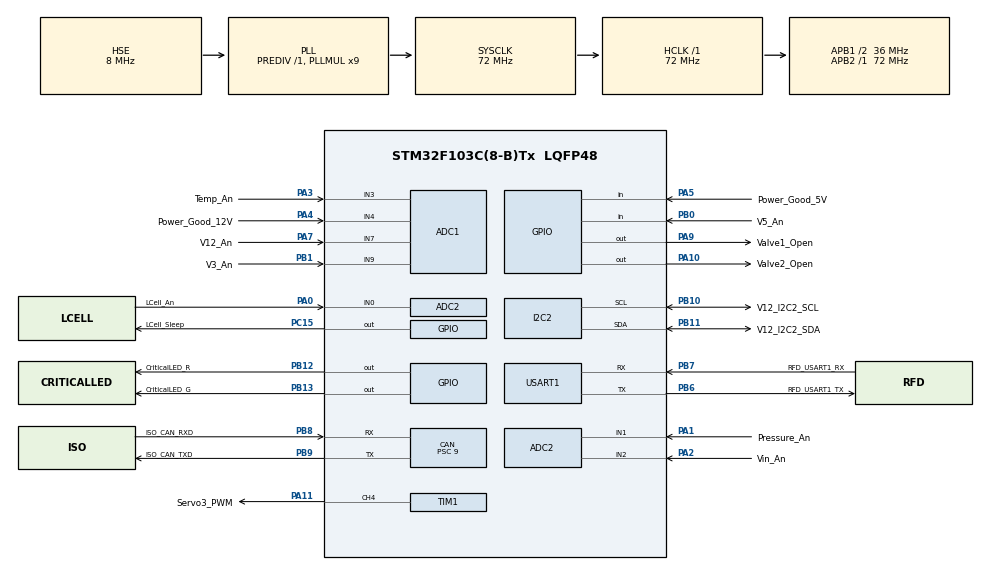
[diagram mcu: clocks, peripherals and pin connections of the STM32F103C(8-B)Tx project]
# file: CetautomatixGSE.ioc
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ADC1.Channel-0\#ChannelRegularConversion=ADC_CHANNEL_3
ADC1.Channel-1\#ChannelRegularConversion=ADC_CHANNEL_4
ADC1.Channel-2\#ChannelRegularConversion=ADC_CHANNEL_7
ADC1.Channel-3\#ChannelRegularConversion=ADC_CHANNEL_9
ADC1.ExternalTrigConv=ADC_EXTERNALTRIGCONV_T3_TRGO
ADC1.Mode=ADC_DUALMODE_REGSIMULT
ADC1.NbrOfConversion=4
ADC1.NbrOfConversionFlag=1
ADC1.Rank-0\#ChannelRegularConversion=1
ADC1.Rank-1\#ChannelRegularConversion=2
ADC1.Rank-2\#ChannelRegularConversion=3
ADC1.Rank-3\#ChannelRegularConversion=4
ADC1.SamplingTime-0\#ChannelRegularConversion=ADC_SAMPLETIME_71CYCLES_5
ADC1.SamplingTime-1\#ChannelRegularConversion=ADC_SAMPLETIME_71CYCLES_5
ADC1.SamplingTime-2\#ChannelRegularConversion=ADC_SAMPLETIME_71CYCLES_5
ADC1.SamplingTime-3\#ChannelRegularConversion=ADC_SAMPLETIME_71CYCLES_5
ADC1.master=1
ADC2.Channel-0\#ChannelRegularConversion=ADC_CHANNEL_0
ADC2.Channel-1\#ChannelRegularConversion=ADC_CHANNEL_1
ADC2.Channel-2\#ChannelRegularConversion=ADC_CHANNEL_2
ADC2.Channel-3\#ChannelRegularConversion=ADC_CHANNEL_2
ADC2.Mode=ADC_DUALMODE_REGSIMULT
ADC2.NbrOfConversion=4
ADC2.NbrOfConversionFlag=1
ADC2.Rank-0\#ChannelRegularConversion=1
ADC2.Rank-1\#ChannelRegularConversion=2
ADC2.Rank-2\#ChannelRegularConversion=3
ADC2.Rank-3\#ChannelRegularConversion=4
ADC2.SamplingTime-0\#ChannelRegularConversion=ADC_SAMPLETIME_71CYCLES_5
ADC2.SamplingTime-1\#ChannelRegularConversion=ADC_SAMPLETIME_71CYCLES_5
ADC2.SamplingTime-2\#ChannelRegularConversion=ADC_SAMPLETIME_71CYCLES_5
ADC2.SamplingTime-3\#ChannelRegularConversion=ADC_SAMPLETIME_71CYCLES_5
CAN.ABOM=ENABLE
CAN.BS1=CAN_BS1_13TQ
CAN.BS2=CAN_BS2_2TQ
CAN.CalculateBaudRate=250000
CAN.CalculateTimeBit=4000
CAN.CalculateTimeQuantum=250.0
CAN.NART=ENABLE
CAN.Prescaler=9
Dma.ADC1.0.Direction=DMA_PERIPH_TO_MEMORY
Dma.ADC1.0.Instance=DMA1_Channel1
Dma.ADC1.0.MemDataAlignment=DMA_MDATAALIGN_WORD
Dma.ADC1.0.MemInc=DMA_MINC_ENABLE
Dma.ADC1.0.Mode=DMA_CIRCULAR
Dma.ADC1.0.PeriphDataAlignment=DMA_PDATAALIGN_WORD
Dma.ADC1.0.PeriphInc=DMA_PINC_DISABLE
Dma.ADC1.0.Priority=DMA_PRIORITY_MEDIUM
Dma.Request0=ADC1
Dma.Request1=USART1_RX
Dma.Request2=USART1_TX
Dma.USART1_RX.1.Direction=DMA_PERIPH_TO_MEMORY
Dma.USART1_RX.1.Instance=DMA1_Channel5
Dma.USART1_RX.1.MemDataAlignment=DMA_MDATAALIGN_BYTE
Dma.USART1_RX.1.MemInc=DMA_MINC_ENABLE
Dma.USART1_RX.1.Mode=DMA_NORMAL
Dma.USART1_RX.1.PeriphDataAlignment=DMA_PDATAALIGN_BYTE
Dma.USART1_RX.1.PeriphInc=DMA_PINC_DISABLE
Dma.USART1_RX.1.Priority=DMA_PRIORITY_HIGH
Dma.USART1_TX.2.Direction=DMA_MEMORY_TO_PERIPH
Dma.USART1_TX.2.Instance=DMA1_Channel4
Dma.USART1_TX.2.MemDataAlignment=DMA_MDATAALIGN_BYTE
Dma.USART1_TX.2.MemInc=DMA_MINC_ENABLE
Dma.USART1_TX.2.Mode=DMA_NORMAL
Dma.USART1_TX.2.PeriphDataAlignment=DMA_PDATAALIGN_BYTE
Dma.USART1_TX.2.PeriphInc=DMA_PINC_DISABLE
Dma.USART1_TX.2.Priority=DMA_PRIORITY_LOW
I2C2.I2C_Mode=I2C_Fast
Mcu.Family=STM32F1
Mcu.Name=STM32F103C(8-B)Tx
Mcu.Package=LQFP48
NVIC.CAN1_RX1_IRQn=true\:0\:0\:false\:false\:true\:true\:true\:true
NVIC.CAN1_SCE_IRQn=true\:0\:0\:false\:false\:true\:true\:true\:true
NVIC.DMA1_Channel1_IRQn=true\:0\:0\:false\:false\:true\:false\:true\:true
NVIC.DMA1_Channel4_IRQn=true\:0\:0\:false\:false\:true\:false\:true\:true
NVIC.DMA1_Channel5_IRQn=true\:0\:0\:false\:false\:true\:false\:true\:true
NVIC.PriorityGroup=NVIC_PRIORITYGROUP_4
NVIC.USART1_IRQn=true\:0\:0\:false\:false\:true\:true\:true\:true
NVIC.USB_LP_CAN1_RX0_IRQn=true\:0\:0\:false\:false\:true\:true\:true\:true
PA0-WKUP.GPIO_Label=LCell_An
PA0-WKUP.Signal=ADCx_IN0
PA1.GPIO_Label=Pressure_An
PA1.Signal=ADCx_IN1
PA10.GPIO_Label=Valve2_Open
PA10.Signal=GPIO_Output
PA11.GPIO_Label=Servo3_PWM
PA11.Signal=S_TIM1_CH4
PA13.GPIO_Label=SYS_SWDIO
PA13.Mode=Trace_Asynchronous_SW
PA13.Signal=SYS_JTMS-SWDIO
PA14.GPIO_Label=SYS_SWCLK
PA14.Mode=Trace_Asynchronous_SW
PA14.Signal=SYS_JTCK-SWCLK
PA2.GPIO_Label=Vin_An
PA2.Signal=ADCx_IN2
PA3.GPIO_Label=Temp_An
PA3.Signal=ADCx_IN3
PA4.GPIO_Label=Power_Good_12V
PA4.Signal=ADCx_IN4
PA5.GPIO_Label=Power_Good_5V
PA5.Signal=GPIO_Input
PA7.GPIO_Label=V12_An
PA7.Signal=ADCx_IN7
PA9.GPIO_Label=Valve1_Open
PA9.Signal=GPIO_Output
PB0.GPIO_Label=V5_An
PB0.Signal=GPIO_Input
PB1.GPIO_Label=V3_An
PB1.Signal=ADCx_IN9
PB10.GPIO_Label=V12_I2C2_SCL
PB10.Mode=I2C
PB10.Signal=I2C2_SCL
PB11.GPIO_Label=V12_I2C2_SDA
PB11.Mode=I2C
PB11.Signal=I2C2_SDA
PB12.GPIO_Label=CriticalLED_R
PB12.Signal=GPIO_Output
PB13.GPIO_Label=CriticalLED_G
PB13.Signal=GPIO_Output
PB3.GPIO_Label=SYS_SWO
PB3.Mode=Trace_Asynchronous_SW
PB3.Signal=SYS_JTDO-TRACESWO
PB6.GPIO_Label=RFD_USART1_TX
PB6.Mode=Asynchronous
PB6.Signal=USART1_TX
PB7.GPIO_Label=RFD_USART1_RX
PB7.Mode=Asynchronous
PB7.Signal=USART1_RX
PB8.GPIO_Label=ISO_CAN_RXD
PB8.Mode=CAN_Activate
PB8.Signal=CAN_RX
PB9.GPIO_Label=ISO_CAN_TXD
PB9.Mode=CAN_Activate
PB9.Signal=CAN_TX
PC15-OSC32_OUT.GPIO_Label=LCell_Sleep
PC15-OSC32_OUT.Signal=GPIO_Output
PD0-OSC_IN.GPIO_Label=OSC_IN
PD0-OSC_IN.Mode=HSE-External-Oscillator
PD0-OSC_IN.Signal=RCC_OSC_IN
PD1-OSC_OUT.GPIO_Label=OSC_OUT
PD1-OSC_OUT.Mode=HSE-External-Oscillator
PD1-OSC_OUT.Signal=RCC_OSC_OUT
ProjectManager.HeapSize=0x200
ProjectManager.StackSize=0x400
ProjectManager.TargetToolchain=STM32CubeIDE
RCC.ADCPresc=RCC_ADCPCLK2_DIV6
RCC.AHBFreq_Value=72000000
RCC.APB1CLKDivider=RCC_HCLK_DIV2
RCC.APB1Freq_Value=36000000
RCC.APB1TimFreq_Value=72000000
RCC.APB2Freq_Value=72000000
RCC.APB2TimFreq_Value=72000000
RCC.HCLKFreq_Value=72000000
RCC.PLLMUL=RCC_PLL_MUL9
RCC.PLLSourceVirtual=RCC_PLLSOURCE_HSE
RCC.SYSCLKFreq_VALUE=72000000
RCC.SYSCLKSource=RCC_SYSCLKSOURCE_PLLCLK
RCC.USBFreq_Value=72000000
SH.ADCx_IN0.0=ADC2_IN0,IN0
SH.ADCx_IN1.0=ADC2_IN1,IN1
SH.ADCx_IN2.0=ADC2_IN2,IN2
SH.ADCx_IN3.0=ADC1_IN3,IN3
SH.ADCx_IN4.0=ADC1_IN4,IN4
SH.ADCx_IN7.0=ADC1_IN7,IN7
SH.ADCx_IN9.0=ADC1_IN9,IN9
SH.S_TIM1_CH4.0=TIM1_CH4,PWM Generation4 CH4
TIM1.Channel-PWM\ Generation4\ CH4=TIM_CHANNEL_4
TIM3.Period=999
TIM3.Prescaler=287
TIM3.TIM_MasterOutputTrigger=TIM_TRGO_UPDATE
USART1.VirtualMode=VM_ASYNC
VP_CRC_VS_CRC.Mode=CRC_Activate
VP_TIM1_VS_ClockSourceINT.Mode=Internal
VP_TIM3_VS_ClockSourceINT.Mode=Internal
board=custom

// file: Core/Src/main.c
/* USER CODE BEGIN Header */
/**
  ******************************************************************************
  * @file           : main.c
  * @brief          : Main program body
  ******************************************************************************
  * @attention
  *
  * Copyright (c) 2026 STMicroelectronics.
  * All rights reserved.
  *
  * This software is licensed under terms that can be found in the LICENSE file
  * in the root directory of this software component.
  * If no LICENSE file comes with this software, it is provided AS-IS.
  *
  ******************************************************************************
  */
/* USER CODE END Header */
#include <GAUL/Drivers/can_fifo.h>
#include <GAUL/Drivers/rfd900x.h>
#include "main.h"

ADC_HandleTypeDef hadc1;
ADC_HandleTypeDef hadc2;
DMA_HandleTypeDef hdma_adc1;

CAN_HandleTypeDef hcan;

CRC_HandleTypeDef hcrc;

I2C_HandleTypeDef hi2c2;

TIM_HandleTypeDef htim1;
TIM_HandleTypeDef htim3;

UART_HandleTypeDef huart1;
DMA_HandleTypeDef hdma_usart1_rx;
DMA_HandleTypeDef hdma_usart1_tx;

/* USER CODE BEGIN PV */
rfd900x_t rfd_dev;
can_t can_dev;
/* USER CODE END PV */

void SystemClock_Config(void);
static void MX_GPIO_Init(void);
static void MX_DMA_Init(void);
static void MX_ADC2_Init(void);
static void MX_CAN_Init(void);
static void MX_CRC_Init(void);
static void MX_TIM1_Init(void);
static void MX_ADC1_Init(void);
static void MX_USART1_UART_Init(void);
static void MX_I2C2_Init(void);
static void MX_TIM3_Init(void);

int main(void)
{

  /* MCU Configuration--------------------------------------------------------*/

  /* Reset of all peripherals, Initializes the Flash interface and the Systick. */
  HAL_Init();

  /* Configure the system clock */
  SystemClock_Config();

  /* Initialize all configured peripherals */
  MX_GPIO_Init();
  MX_DMA_Init();
  MX_ADC2_Init();
  MX_CAN_Init();
  MX_CRC_Init();
  MX_TIM1_Init();
  MX_ADC1_Init();
  MX_USART1_UART_Init();
  MX_I2C2_Init();
  MX_TIM3_Init();

  /* Infinite loop */
  while (1)
  {

  }
}

void SystemClock_Config(void)
{
  RCC_OscInitTypeDef RCC_OscInitStruct = {0};
  RCC_ClkInitTypeDef RCC_ClkInitStruct = {0};
  RCC_PeriphCLKInitTypeDef PeriphClkInit = {0};

  /** Initializes the RCC Oscillators according to the specified parameters
  * in the RCC_OscInitTypeDef structure.
  */
  RCC_OscInitStruct.OscillatorType = RCC_OSCILLATORTYPE_HSE;
  RCC_OscInitStruct.HSEState = RCC_HSE_ON;
  RCC_OscInitStruct.HSEPredivValue = RCC_HSE_PREDIV_DIV1;
  RCC_OscInitStruct.HSIState = RCC_HSI_ON;
  RCC_OscInitStruct.PLL.PLLState = RCC_PLL_ON;
  RCC_OscInitStruct.PLL.PLLSource = RCC_PLLSOURCE_HSE;
  RCC_OscInitStruct.PLL.PLLMUL = RCC_PLL_MUL9;
  if (HAL_RCC_OscConfig(&RCC_OscInitStruct) != HAL_OK)
  {
    Error_Handler();
  }

  /** Initializes the CPU, AHB and APB buses clocks
  */
  RCC_ClkInitStruct.ClockType = RCC_CLOCKTYPE_HCLK|RCC_CLOCKTYPE_SYSCLK
                              |RCC_CLOCKTYPE_PCLK1|RCC_CLOCKTYPE_PCLK2;
  RCC_ClkInitStruct.SYSCLKSource = RCC_SYSCLKSOURCE_PLLCLK;
  RCC_ClkInitStruct.AHBCLKDivider = RCC_SYSCLK_DIV1;
  RCC_ClkInitStruct.APB1CLKDivider = RCC_HCLK_DIV2;
  RCC_ClkInitStruct.APB2CLKDivider = RCC_HCLK_DIV1;

  if (HAL_RCC_ClockConfig(&RCC_ClkInitStruct, FLASH_LATENCY_2) != HAL_OK)
  {
    Error_Handler();
  }
  PeriphClkInit.PeriphClockSelection = RCC_PERIPHCLK_ADC;
  PeriphClkInit.AdcClockSelection = RCC_ADCPCLK2_DIV6;
  if (HAL_RCCEx_PeriphCLKConfig(&PeriphClkInit) != HAL_OK)
  {
    Error_Handler();
  }
}

static void MX_ADC1_Init(void)
{

  ADC_MultiModeTypeDef multimode = {0};
  ADC_ChannelConfTypeDef sConfig = {0};

  /** Common config
  */
  hadc1.Instance = ADC1;
  hadc1.Init.ScanConvMode = ADC_SCAN_ENABLE;
  hadc1.Init.ContinuousConvMode = DISABLE;
  hadc1.Init.DiscontinuousConvMode = DISABLE;
  hadc1.Init.ExternalTrigConv = ADC_EXTERNALTRIGCONV_T3_TRGO;
  hadc1.Init.DataAlign = ADC_DATAALIGN_RIGHT;
  hadc1.Init.NbrOfConversion = 4;
  if (HAL_ADC_Init(&hadc1) != HAL_OK)
  {
    Error_Handler();
  }

  /** Configure the ADC multi-mode
  */
  multimode.Mode = ADC_DUALMODE_REGSIMULT;
  if (HAL_ADCEx_MultiModeConfigChannel(&hadc1, &multimode) != HAL_OK)
  {
    Error_Handler();
  }

  /** Configure Regular Channel
  */
  sConfig.Channel = ADC_CHANNEL_3;
  sConfig.Rank = ADC_REGULAR_RANK_1;
  sConfig.SamplingTime = ADC_SAMPLETIME_71CYCLES_5;
  if (HAL_ADC_ConfigChannel(&hadc1, &sConfig) != HAL_OK)
  {
    Error_Handler();
  }

  /** Configure Regular Channel
  */
  sConfig.Channel = ADC_CHANNEL_4;
  sConfig.Rank = ADC_REGULAR_RANK_2;
  if (HAL_ADC_ConfigChannel(&hadc1, &sConfig) != HAL_OK)
  {
    Error_Handler();
  }

  /** Configure Regular Channel
  */
  sConfig.Channel = ADC_CHANNEL_7;
  sConfig.Rank = ADC_REGULAR_RANK_3;
  if (HAL_ADC_ConfigChannel(&hadc1, &sConfig) != HAL_OK)
  {
    Error_Handler();
  }

  /** Configure Regular Channel
  */
  sConfig.Channel = ADC_CHANNEL_9;
  sConfig.Rank = ADC_REGULAR_RANK_4;
  if (HAL_ADC_ConfigChannel(&hadc1, &sConfig) != HAL_OK)
  {
    Error_Handler();
  }

}

static void MX_ADC2_Init(void)
{

  ADC_ChannelConfTypeDef sConfig = {0};

  /** Common config
  */
  hadc2.Instance = ADC2;
  hadc2.Init.ScanConvMode = ADC_SCAN_ENABLE;
  hadc2.Init.ContinuousConvMode = DISABLE;
  hadc2.Init.DiscontinuousConvMode = DISABLE;
  hadc2.Init.ExternalTrigConv = ADC_SOFTWARE_START;
  hadc2.Init.DataAlign = ADC_DATAALIGN_RIGHT;
  hadc2.Init.NbrOfConversion = 4;
  if (HAL_ADC_Init(&hadc2) != HAL_OK)
  {
    Error_Handler();
  }

  /** Configure Regular Channel
  */
  sConfig.Channel = ADC_CHANNEL_0;
  sConfig.Rank = ADC_REGULAR_RANK_1;
  sConfig.SamplingTime = ADC_SAMPLETIME_71CYCLES_5;
  if (HAL_ADC_ConfigChannel(&hadc2, &sConfig) != HAL_OK)
  {
    Error_Handler();
  }

  /** Configure Regular Channel
  */
  sConfig.Channel = ADC_CHANNEL_1;
  sConfig.Rank = ADC_REGULAR_RANK_2;
  if (HAL_ADC_ConfigChannel(&hadc2, &sConfig) != HAL_OK)
  {
    Error_Handler();
  }

  /** Configure Regular Channel
  */
  sConfig.Channel = ADC_CHANNEL_2;
  sConfig.Rank = ADC_REGULAR_RANK_3;
  if (HAL_ADC_ConfigChannel(&hadc2, &sConfig) != HAL_OK)
  {
    Error_Handler();
  }

  /** Configure Regular Channel
  */
  sConfig.Rank = ADC_REGULAR_RANK_4;
  if (HAL_ADC_ConfigChannel(&hadc2, &sConfig) != HAL_OK)
  {
    Error_Handler();
  }

}

static void MX_CAN_Init(void)
{

  hcan.Instance = CAN1;
  hcan.Init.Prescaler = 9;
  hcan.Init.Mode = CAN_MODE_NORMAL;
  hcan.Init.SyncJumpWidth = CAN_SJW_1TQ;
  hcan.Init.TimeSeg1 = CAN_BS1_13TQ;
  hcan.Init.TimeSeg2 = CAN_BS2_2TQ;
  hcan.Init.TimeTriggeredMode = DISABLE;
  hcan.Init.AutoBusOff = ENABLE;
  hcan.Init.AutoWakeUp = DISABLE;
  hcan.Init.AutoRetransmission = ENABLE;
  hcan.Init.ReceiveFifoLocked = DISABLE;
  hcan.Init.TransmitFifoPriority = DISABLE;
  if (HAL_CAN_Init(&hcan) != HAL_OK)
  {
    Error_Handler();
  }

}

static void MX_CRC_Init(void)
{

  hcrc.Instance = CRC;
  if (HAL_CRC_Init(&hcrc) != HAL_OK)
  {
    Error_Handler();
  }

}

static void MX_I2C2_Init(void)
{

  hi2c2.Instance = I2C2;
  hi2c2.Init.ClockSpeed = 400000;
  hi2c2.Init.DutyCycle = I2C_DUTYCYCLE_2;
  hi2c2.Init.OwnAddress1 = 0;
  hi2c2.Init.AddressingMode = I2C_ADDRESSINGMODE_7BIT;
  hi2c2.Init.DualAddressMode = I2C_DUALADDRESS_DISABLE;
  hi2c2.Init.OwnAddress2 = 0;
  hi2c2.Init.GeneralCallMode = I2C_GENERALCALL_DISABLE;
  hi2c2.Init.NoStretchMode = I2C_NOSTRETCH_DISABLE;
  if (HAL_I2C_Init(&hi2c2) != HAL_OK)
  {
    Error_Handler();
  }

}

static void MX_TIM1_Init(void)
{

  TIM_ClockConfigTypeDef sClockSourceConfig = {0};
  TIM_MasterConfigTypeDef sMasterConfig = {0};
  TIM_OC_InitTypeDef sConfigOC = {0};
  TIM_BreakDeadTimeConfigTypeDef sBreakDeadTimeConfig = {0};

  htim1.Instance = TIM1;
  htim1.Init.Prescaler = 0;
  htim1.Init.CounterMode = TIM_COUNTERMODE_UP;
  htim1.Init.Period = 65535;
  htim1.Init.ClockDivision = TIM_CLOCKDIVISION_DIV1;
  htim1.Init.RepetitionCounter = 0;
  htim1.Init.AutoReloadPreload = TIM_AUTORELOAD_PRELOAD_DISABLE;
  if (HAL_TIM_Base_Init(&htim1) != HAL_OK)
  {
    Error_Handler();
  }
  sClockSourceConfig.ClockSource = TIM_CLOCKSOURCE_INTERNAL;
  if (HAL_TIM_ConfigClockSource(&htim1, &sClockSourceConfig) != HAL_OK)
  {
    Error_Handler();
  }
  if (HAL_TIM_PWM_Init(&htim1) != HAL_OK)
  {
    Error_Handler();
  }
  sMasterConfig.MasterOutputTrigger = TIM_TRGO_RESET;
  sMasterConfig.MasterSlaveMode = TIM_MASTERSLAVEMODE_DISABLE;
  if (HAL_TIMEx_MasterConfigSynchronization(&htim1, &sMasterConfig) != HAL_OK)
  {
    Error_Handler();
  }
  sConfigOC.OCMode = TIM_OCMODE_PWM1;
  sConfigOC.Pulse = 0;
  sConfigOC.OCPolarity = TIM_OCPOLARITY_HIGH;
  sConfigOC.OCFastMode = TIM_OCFAST_DISABLE;
  sConfigOC.OCIdleState = TIM_OCIDLESTATE_RESET;
  sConfigOC.OCNIdleState = TIM_OCNIDLESTATE_RESET;
  if (HAL_TIM_PWM_ConfigChannel(&htim1, &sConfigOC, TIM_CHANNEL_4) != HAL_OK)
  {
    Error_Handler();
  }
  sBreakDeadTimeConfig.OffStateRunMode = TIM_OSSR_DISABLE;
  sBreakDeadTimeConfig.OffStateIDLEMode = TIM_OSSI_DISABLE;
  sBreakDeadTimeConfig.LockLevel = TIM_LOCKLEVEL_OFF;
  sBreakDeadTimeConfig.DeadTime = 0;
  sBreakDeadTimeConfig.BreakState = TIM_BREAK_DISABLE;
  sBreakDeadTimeConfig.BreakPolarity = TIM_BREAKPOLARITY_HIGH;
  sBreakDeadTimeConfig.AutomaticOutput = TIM_AUTOMATICOUTPUT_DISABLE;
  if (HAL_TIMEx_ConfigBreakDeadTime(&htim1, &sBreakDeadTimeConfig) != HAL_OK)
  {
    Error_Handler();
  }
  HAL_TIM_MspPostInit(&htim1);

}

static void MX_TIM3_Init(void)
{

  TIM_ClockConfigTypeDef sClockSourceConfig = {0};
  TIM_MasterConfigTypeDef sMasterConfig = {0};

  htim3.Instance = TIM3;
  htim3.Init.Prescaler = 287;
  htim3.Init.CounterMode = TIM_COUNTERMODE_UP;
  htim3.Init.Period = 999;
  htim3.Init.ClockDivision = TIM_CLOCKDIVISION_DIV1;
  htim3.Init.AutoReloadPreload = TIM_AUTORELOAD_PRELOAD_DISABLE;
  if (HAL_TIM_Base_Init(&htim3) != HAL_OK)
  {
    Error_Handler();
  }
  sClockSourceConfig.ClockSource = TIM_CLOCKSOURCE_INTERNAL;
  if (HAL_TIM_ConfigClockSource(&htim3, &sClockSourceConfig) != HAL_OK)
  {
    Error_Handler();
  }
  sMasterConfig.MasterOutputTrigger = TIM_TRGO_UPDATE;
  sMasterConfig.MasterSlaveMode = TIM_MASTERSLAVEMODE_DISABLE;
  if (HAL_TIMEx_MasterConfigSynchronization(&htim3, &sMasterConfig) != HAL_OK)
  {
    Error_Handler();
  }

}

static void MX_USART1_UART_Init(void)
{

  huart1.Instance = USART1;
  huart1.Init.BaudRate = 115200;
  huart1.Init.WordLength = UART_WORDLENGTH_8B;
  huart1.Init.StopBits = UART_STOPBITS_1;
  huart1.Init.Parity = UART_PARITY_NONE;
  huart1.Init.Mode = UART_MODE_TX_RX;
  huart1.Init.HwFlowCtl = UART_HWCONTROL_NONE;
  huart1.Init.OverSampling = UART_OVERSAMPLING_16;
  if (HAL_UART_Init(&huart1) != HAL_OK)
  {
    Error_Handler();
  }

}

static void MX_DMA_Init(void)
{

  /* DMA controller clock enable */
  __HAL_RCC_DMA1_CLK_ENABLE();

  /* DMA interrupt init */
  /* DMA1_Channel1_IRQn interrupt configuration */
  HAL_NVIC_SetPriority(DMA1_Channel1_IRQn, 0, 0);
  HAL_NVIC_EnableIRQ(DMA1_Channel1_IRQn);
  /* DMA1_Channel4_IRQn interrupt configuration */
  HAL_NVIC_SetPriority(DMA1_Channel4_IRQn, 0, 0);
  HAL_NVIC_EnableIRQ(DMA1_Channel4_IRQn);
  /* DMA1_Channel5_IRQn interrupt configuration */
  HAL_NVIC_SetPriority(DMA1_Channel5_IRQn, 0, 0);
  HAL_NVIC_EnableIRQ(DMA1_Channel5_IRQn);

}

static void MX_GPIO_Init(void)
{
  GPIO_InitTypeDef GPIO_InitStruct = {0};

  /* GPIO Ports Clock Enable */
  __HAL_RCC_GPIOC_CLK_ENABLE();
  __HAL_RCC_GPIOD_CLK_ENABLE();
  __HAL_RCC_GPIOA_CLK_ENABLE();
  __HAL_RCC_GPIOB_CLK_ENABLE();

  /*Configure GPIO pin Output Level */
  HAL_GPIO_WritePin(LCell_Sleep_GPIO_Port, LCell_Sleep_Pin, GPIO_PIN_RESET);

  /*Configure GPIO pin Output Level */
  HAL_GPIO_WritePin(GPIOB, CriticalLED_R_Pin|CriticalLED_G_Pin, GPIO_PIN_RESET);

  /*Configure GPIO pin Output Level */
  HAL_GPIO_WritePin(GPIOA, Valve1_Open_Pin|Valve2_Open_Pin, GPIO_PIN_RESET);

  /*Configure GPIO pin : LCell_Sleep_Pin */
  GPIO_InitStruct.Pin = LCell_Sleep_Pin;
  GPIO_InitStruct.Mode = GPIO_MODE_OUTPUT_PP;
  GPIO_InitStruct.Pull = GPIO_NOPULL;
  GPIO_InitStruct.Speed = GPIO_SPEED_FREQ_LOW;
  HAL_GPIO_Init(LCell_Sleep_GPIO_Port, &GPIO_InitStruct);

  /*Configure GPIO pin : Power_Good_5V_Pin */
  GPIO_InitStruct.Pin = Power_Good_5V_Pin;
  GPIO_InitStruct.Mode = GPIO_MODE_INPUT;
  GPIO_InitStruct.Pull = GPIO_NOPULL;
  HAL_GPIO_Init(Power_Good_5V_GPIO_Port, &GPIO_InitStruct);

  /*Configure GPIO pin : V5_An_Pin */
  GPIO_InitStruct.Pin = V5_An_Pin;
  GPIO_InitStruct.Mode = GPIO_MODE_INPUT;
  GPIO_InitStruct.Pull = GPIO_NOPULL;
  HAL_GPIO_Init(V5_An_GPIO_Port, &GPIO_InitStruct);

  /*Configure GPIO pins : CriticalLED_R_Pin CriticalLED_G_Pin */
  GPIO_InitStruct.Pin = CriticalLED_R_Pin|CriticalLED_G_Pin;
  GPIO_InitStruct.Mode = GPIO_MODE_OUTPUT_PP;
  GPIO_InitStruct.Pull = GPIO_NOPULL;
  GPIO_InitStruct.Speed = GPIO_SPEED_FREQ_LOW;
  HAL_GPIO_Init(GPIOB, &GPIO_InitStruct);

  /*Configure GPIO pins : Valve1_Open_Pin Valve2_Open_Pin */
  GPIO_InitStruct.Pin = Valve1_Open_Pin|Valve2_Open_Pin;
  GPIO_InitStruct.Mode = GPIO_MODE_OUTPUT_PP;
  GPIO_InitStruct.Pull = GPIO_NOPULL;
  GPIO_InitStruct.Speed = GPIO_SPEED_FREQ_LOW;
  HAL_GPIO_Init(GPIOA, &GPIO_InitStruct);

}

void Error_Handler(void)
{
  __disable_irq();
  while (1)
  {
  }
}
